# GD32A72_A74x register map
File version: 1.0
CPU: CM7 r2p1, little endian, MPU, FPU, DSP, 4 interrupt priority bits
Registers are 32-bit, read-write, reset 0x0 unless marked. A register's access mark holds for its fields unless they carry their own. Offsets are from the block's base; [hi:lo] are bit positions; {n}, {i} and the like mark numbered series.

## SENT — Single edge Nibble transmission
Base 0x40006000
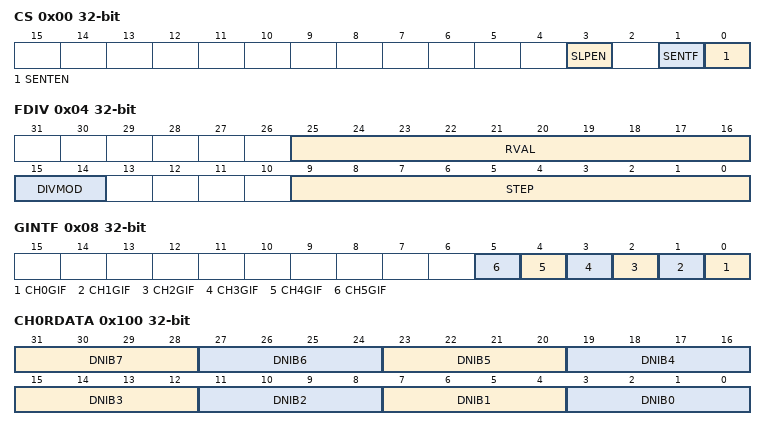
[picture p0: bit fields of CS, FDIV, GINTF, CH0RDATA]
0x00 CS access per field — Control and status register
  [3] SLPEN rw — SENT sleep mode enable
  [1] SENTF ro — SENT status
  [0] SENTEN rw — SENT enable
0x04 FDIV access per field — Fractional divider register
  [25:16] RVAL ro — Result value
  [15:14] DIVMOD rw — Fractional divider mode
  [9:0] STEP rw — Step value
0x08 GINTF ro — Global interrupt flag register
  [n] CH{n}GIF (n=0..5) — Global interrupt flag of channel {n}
0x0C TS ro — Time stamp register
  [31:0] TS — Time stamp
0x10 TSPSC — Time stamp prescaler register
  [19:0] TSPSC — Dividing factor for the time stamp prescaler
0x100 CH0RDATA ro — Channel 0 receive data register
  [4n+3:4n] DNIB{n} (n=1..7) — Channel 0 receive data Nibble {n}
  [3:0] DNIB0 — channel x receive data nibble 0
0x104 CH0PSC — Channel 0 prescaler register
  [11:0] PSC — channel x prescaler factor
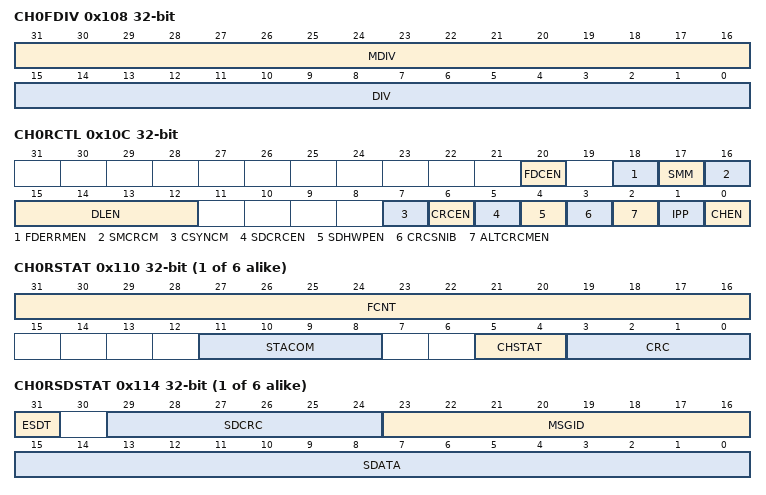
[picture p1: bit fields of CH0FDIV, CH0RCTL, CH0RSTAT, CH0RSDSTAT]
0x108 CH0FDIV access per field — Channel 0 fractional divider register
  [31:16] MDIV ro — channel x measured fractional divider factor
  [15:0] DIV rw — channel x fractional divider factor
0x10C CH0RCTL — Channel 0 receive control register
  [20] FDCEN — Frequency drift check enable
  [18] FDERRMEN — Frequency drift error mode enable
  [17] SMM — Serial message mode
  [16] SMCRCM — Serial message CRC mode
  [15:12] DLEN — Data length
  [7] CSYNCM — Consecutive synchronization check mode
  [6] CRCEN — CRC enable
  [5] SDCRCEN — Serial data CRC enable
  [4] SDHWPEN — Serial data hardware parse enable
  [3] CRCSNIB — Whether Status and Communication Nibble is included in CRC calculation of fast channel (signal) data
  [2] ALTCRCMEN — Alternative CRC mode enable
  [1] IPP — Ignore pause pulse
  [0] CHEN — Channel enable
{0x110+0x100*i} CH{i}RSTAT ro (i=0..5) — Channel {i} receive status register
  [31:16] FCNT — counter of a frame, including pause pulse
  [11:8] STACOM — status and communication nibble
  [5:4] CHSTAT — channel status
  [3:0] CRC — crc nibble
{0x114+0x100*i} CH{i}RSDSTAT ro (i=0..5) — Channel {i} receive serial data and status register
  [31] ESDT — enhanced serial data message type
  [29:24] SDCRC — serial data crc value
  [23:16] MSGID — message id
  [15:0] SDATA — serial data
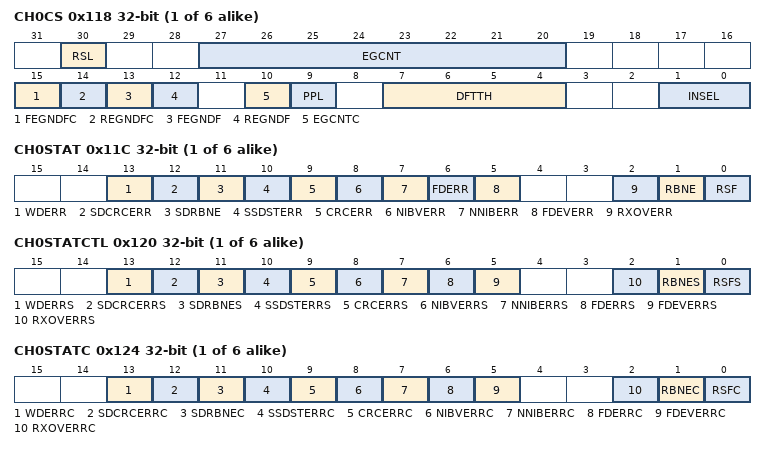
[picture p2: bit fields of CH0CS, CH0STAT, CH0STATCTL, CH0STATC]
{0x118+0x100*i} CH{i}CS access per field (i=0..5) — Channel {i} control and status register
  [30] RSL ro — receive signal level
  [27:20] EGCNT ro — edge counter
  [15] FEGNDFC rw — falling edge noise detect flag clear
  [14] REGNDFC rw — rising edge noise detect flag clear
  [13] FEGNDF ro — falling edge noise detect flag
  [12] REGNDF ro — rising edge noise detect flag
  [10] EGCNTC wo — edge counter clear
  [9] PPL rw — pulse polarity
  [7:4] DFTTH rw — digital filter timer threshold
  [1:0] INSEL rw — select input x
{0x11C+0x100*i} CH{i}STAT ro (i=0..5) — Channel {i} status register
  [13] WDERR — watchdog error flag
  [12] SDCRCERR — serial data crc error flag
  [11] SDRBNE — serial data receive buffer not empty flag
  [10] SSDSTERR — short serial data message start bit error flag
  [9] CRCERR — crc error flag
  [8] NIBVERR — nibble value error flag
  [7] NNIBERR — number of nibbles error flag
  [6] FDERR — frequency drift error flag
  [5] FDEVERR — frequency deviation error flag
  [2] RXOVERR — receive buffer overflow error flag
  [1] RBNE — receive buffer not empty flag
  [0] RSF — receive success flag
{0x120+0x100*i} CH{i}STATCTL wo (i=0..5) — Channel {i} status control register
  [13] WDERRS — watchdog error flag set
  [12] SDCRCERRS — serial data crc error flag set
  [11] SDRBNES — serial data receive buffer not empty flag
  [10] SSDSTERRS — short serial data message start bit error flag set
  [9] CRCERRS — crc error flag set
  [8] NIBVERRS — nibble value error flag set
  [7] NNIBERRS — number of nibbles error flag set
  [6] FDERRS — frequency drift error flag set
  [5] FDEVERRS — frequency deviation error flag set
  [2] RXOVERRS — receive buffer overflow error flag set
  [1] RBNES — receive buffer not empty flag set
  [0] RSFS — receive success flag
{0x124+0x100*i} CH{i}STATC wo (i=0..5) — Channel {i} status clear register
  [13] WDERRC — watchdog error flag clear
  [12] SDCRCERRC — serial data crc error flag clear
  [11] SDRBNEC — serial data receive buffer not empty flag clear
  [10] SSDSTERRC — short serial data message start bit error flag clear
  [9] CRCERRC — crc error flag clear
  [8] NIBVERRC — nibble value error flag clear
  [7] NNIBERRC — number of nibbles error flag clear
  [6] FDERRC — frequency drift error flag clear
  [5] FDEVERRC — frequency deviation error flag clear
  [2] RXOVERRC — receive buffer overflow error flag clear
  [1] RBNEC — receive buffer not empty flag clear
  [0] RSFC — receive success flag clear
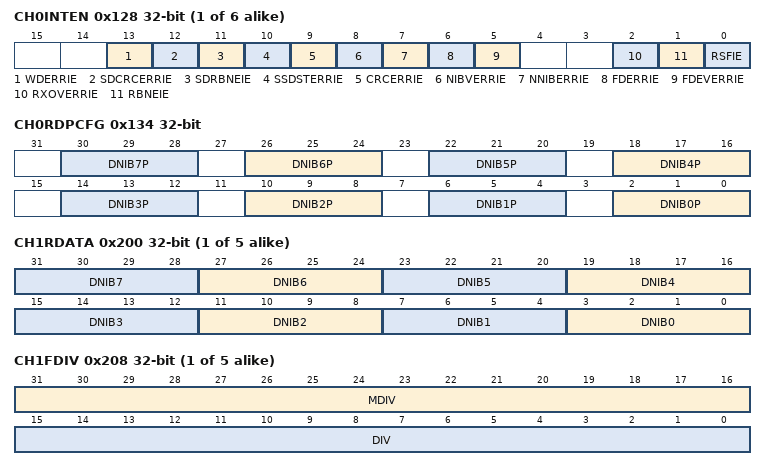
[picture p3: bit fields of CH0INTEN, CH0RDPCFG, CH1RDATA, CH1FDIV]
{0x128+0x100*i} CH{i}INTEN wo (i=0..5) — Channel {i} interrupt enable register
  [13] WDERRIE — watchdog error interrupt enable
  [12] SDCRCERRIE — serial data crc error interrupt enable
  [11] SDRBNEIE — serial data receive buffer not empty interrupt enable
  [10] SSDSTERRIE — short serial data message start bit error interrupt enable
  [9] CRCERRIE — crc error interrupt enable
  [8] NIBVERRIE — nibble value error interrupt enable
  [7] NNIBERRIE — number of nibbles error interrupt enable
  [6] FDERRIE — frequency drift error interrupt enable
  [5] FDEVERRIE — frequency deviation error interrupt enable
  [2] RXOVERRIE — receive buffer overflow error interrupt enable
  [1] RBNEIE — receive buffer not empty interrupt enable
  [0] RSFIE — receive success interrupt enable
0x12C CH0WDGT — Channel 0 watchdog timer register
  [15:0] THOLD — watchdog timer counter threshold value for channel x
0x130 CH0TS ro — Channel 0 receive time stamp register
  [31:0] TS — channel x time stamp
0x134 CH0RDPCFG ro — Channel 0 receive data position configuration register 0
  [4n+2:4n] DNIB{n}P (n=0..7) — channel x receive data nibble {n} position
{0x100+0x100*i} CH{i}RDATA ro (i=1..5) — Channel {i} receive data register
  [4n+3:4n] DNIB{n} (n=0..7) — channel {i} receive data nibble {n}
{0x104+0x100*i} CH{i}PSC (i=1..5) — Channel {i} prescaler register
  [11:0] PSC — channel {i} prescaler factor
{0x108+0x100*i} CH{i}FDIV access per field (i=1..5) — Channel {i} fractional divider register
  [31:16] MDIV ro — channel {i} measured fractional divider factor
  [15:0] DIV rw — channel {i} fractional divider factor
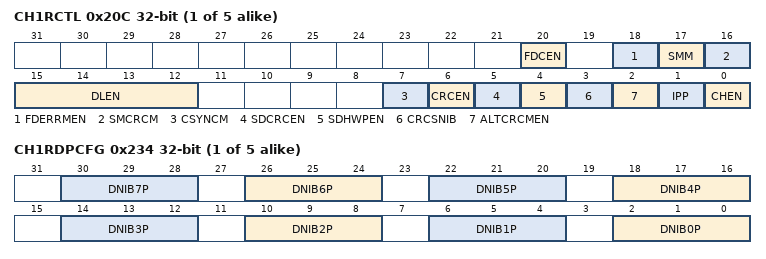
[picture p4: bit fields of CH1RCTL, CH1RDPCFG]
{0x10C+0x100*i} CH{i}RCTL (i=1..5) — Channel {i} receive control register
  [20] FDCEN — frequency drift check enable
  [18] FDERRMEN — frequency drift error mode enable
  [17] SMM — serial message mode
  [16] SMCRCM — serial message crc mode
  [15:12] DLEN — data length
  [7] CSYNCM — consecutive synchronization check mode
  [6] CRCEN — crc enable
  [5] SDCRCEN — serial data crc enable
  [4] SDHWPEN — serial data hardware parse enable
  [3] CRCSNIB — whether status and communication nibble is included in crc calculation of fast channel (signal) data
  [2] ALTCRCMEN — alternative crc mode enable
  [1] IPP — ignore pause pulse
  [0] CHEN — channel enable
{0x12C+0x100*i} CH{i}WDGT (i=1..5) — Channel {i} watchdog timer register
  [15:0] THOLD — watchdog timer counter threshold value for channel {i}
{0x130+0x100*i} CH{i}TS ro (i=1..5) — Channel {i} receive time stamp register
  [31:0] TS — channel {i} time stamp
{0x134+0x100*i} CH{i}RDPCFG ro (i=1..5) — Channel {i} receive data position configuration register {i}
  [4n+2:4n] DNIB{n}P (n=0..7) — channel {i} receive data nibble {n} position
